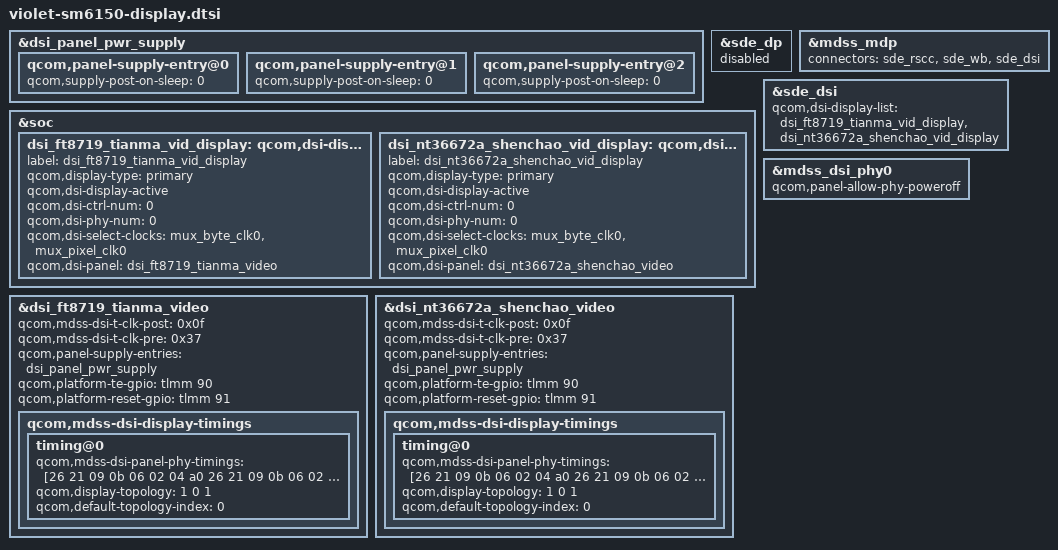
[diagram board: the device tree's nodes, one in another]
/* Copyright (c) 2020, The Linux Foundation. All rights reserved.
 *
 * This program is free software; you can redistribute it and/or modify
 * it under the terms of the GNU General Public License version 2 and
 * only version 2 as published by the Free Software Foundation.
 *
 * This program is distributed in the hope that it will be useful,
 * but WITHOUT ANY WARRANTY; without even the implied warranty of
 * MERCHANTABILITY or FITNESS FOR A PARTICULAR PURPOSE.  See the
 * GNU General Public License for more details.
 */

#include "dsi-panel-ft8719-tianma-fhd-video.dtsi"
#include "dsi-panel-nt36672a-shenchao-fhd-video.dtsi"

&dsi_panel_pwr_supply {
	qcom,panel-supply-entry@0 {
		qcom,supply-post-on-sleep = <0>;
	};

	qcom,panel-supply-entry@1 {
		qcom,supply-post-on-sleep = <0>;
	};

	qcom,panel-supply-entry@2 {
		qcom,supply-post-on-sleep = <0>;
	};
};

&sde_dp {
	status = "disabled";
};

&mdss_mdp {
	connectors = <&sde_rscc &sde_wb &sde_dsi>;
};

&soc {
	dsi_ft8719_tianma_vid_display: qcom,dsi-display@0 {
		label = "dsi_ft8719_tianma_vid_display";
		qcom,display-type = "primary";
		qcom,dsi-display-active;

		qcom,dsi-ctrl-num = <0>;
		qcom,dsi-phy-num = <0>;
		qcom,dsi-select-clocks = "mux_byte_clk0", "mux_pixel_clk0";
		qcom,dsi-panel = <&dsi_ft8719_tianma_video>;
	};

    dsi_nt36672a_shenchao_vid_display: qcom,dsi-display@1 {
		label = "dsi_nt36672a_shenchao_vid_display";
		qcom,display-type = "primary";
		qcom,dsi-display-active;

		qcom,dsi-ctrl-num = <0>;
		qcom,dsi-phy-num = <0>;
		qcom,dsi-select-clocks = "mux_byte_clk0", "mux_pixel_clk0";
		qcom,dsi-panel = <&dsi_nt36672a_shenchao_video>;
	};
};

&sde_dsi {
	qcom,dsi-display-list =
			<&dsi_ft8719_tianma_vid_display
			&dsi_nt36672a_shenchao_vid_display>;
};

&dsi_ft8719_tianma_video {
	qcom,mdss-dsi-t-clk-post = <0x0f>;
	qcom,mdss-dsi-t-clk-pre = <0x37>;
	qcom,panel-supply-entries = <&dsi_panel_pwr_supply>;
	qcom,platform-te-gpio = <&tlmm 90 0>;
	qcom,platform-reset-gpio = <&tlmm 91 0>;
	qcom,mdss-dsi-display-timings {
		timing@0{
			qcom,mdss-dsi-panel-phy-timings =
				[26 21 09 0b 06 02 04 a0
				26 21 09 0b 06 02 04 a0
				26 21 09 0b 06 02 04 a0
				26 21 09 0b 06 02 04 a0
				26 20 0a 0b 06 02 04 a0];
			qcom,display-topology = <1 0 1>;
			qcom,default-topology-index = <0>;
		};
	};
};

&dsi_nt36672a_shenchao_video {
	qcom,mdss-dsi-t-clk-post = <0x0f>;
	qcom,mdss-dsi-t-clk-pre = <0x37>;
	qcom,panel-supply-entries = <&dsi_panel_pwr_supply>;
	qcom,platform-te-gpio = <&tlmm 90 0>;
	qcom,platform-reset-gpio = <&tlmm 91 0>;
	qcom,mdss-dsi-display-timings {
		timing@0{
			qcom,mdss-dsi-panel-phy-timings =
				[26 21 09 0b 06 02 04 a0
				26 21 09 0b 06 02 04 a0
				26 21 09 0b 06 02 04 a0
				26 21 09 0b 06 02 04 a0
				26 20 0a 0b 06 02 04 a0];
			qcom,display-topology = <1 0 1>;
			qcom,default-topology-index = <0>;
		};
	};
};

&mdss_dsi_phy0 {	
       qcom,panel-allow-phy-poweroff;	
};
